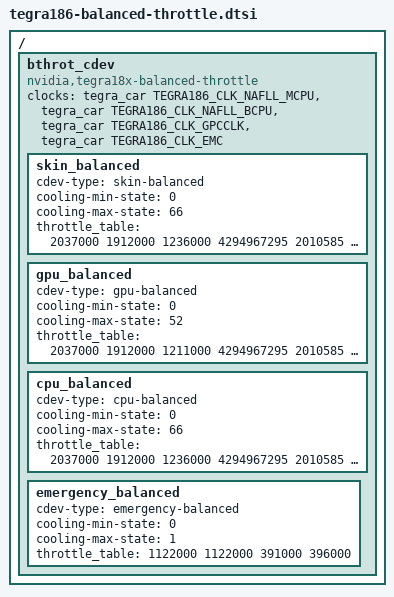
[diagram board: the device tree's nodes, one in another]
/*
 * arch/arm64/boot/dts/tegra186-platforms/tegra186-balanced-throttle.dtsi
 *
 * Copyright (c) 2015-2016, NVIDIA CORPORATION.  All rights reserved.
 *
 * This program is free software; you can redistribute it and/or modify
 * it under the terms of the GNU General Public License as published by
 * the Free Software Foundation; version 2 of the License.
 *
 * This program is distributed in the hope that it will be useful, but WITHOUT
 * ANY WARRANTY; without even the implied warranty of MERCHANTABILITY or
 * FITNESS FOR A PARTICULAR PURPOSE.  See the GNU General Public License for
 * more details.
 *
 * You should have received a copy of the GNU General Public License along
 * with this program; if not, write to the Free Software Foundation, Inc.,
 * 51 Franklin Street, Fifth Floor, Boston, MA  02110-1301, USA.
 *
 */

/{
	bthrot_cdev {
		compatible = "nvidia,tegra18x-balanced-throttle";
		clocks = <&tegra_car TEGRA186_CLK_NAFLL_MCPU>,
				 <&tegra_car TEGRA186_CLK_NAFLL_BCPU>,
				 <&tegra_car TEGRA186_CLK_GPCCLK>,
				 <&tegra_car TEGRA186_CLK_EMC>;
		clock-names = "mcpu", "bcpu", "gpu", "emc";

		skin_balanced {
			cdev-type = "skin-balanced";
			cooling-min-state = <0>;
			cooling-max-state = <66>;
			#cooling-cells = <2>;
			throttle_table = <
				2037000	1912000	1236000	4294967295
				2010585	1887508	1218508	4294967295
				1984169	1863015	1201015	4294967295
				1957754	1838523	1183523	4294967295
				1931338	1814031	1166031	4294967295
				1904923	1789538	1148538	4294967295
				1878508	1765046	1131046	4294967295
				1852092	1740554	1113554	4294967295
				1825677	1716062	1096062	4294967295
				1799262	1691569	1078569	4294967295
				1772846	1667077	1061077	4294967295
				1746431	1642585	1043585	4294967295
				1720015	1618092	1026092	4294967295
				1693600	1593600	1008600	4294967295
				1667185	1569108	991108	4294967295
				1640769	1544615	973615	4294967295
				1614354	1520123	956123	4294967295
				1587938	1495631	938631	4294967295
				1561523	1471138	921138	4294967295
				1535108	1446646	903646	4294967295
				1508692	1422154	886154	4294967295
				1482277	1397662	868662	4294967295
				1455862	1373169	851169	4294967295
				1429446	1348677	833677	4294967295
				1403031	1324185	816185	4294967295
				1376615	1299692	798692	4294967295
				1350200	1275200	781200	4294967295
				1323785	1250708	763708	4294967295
				1297369	1226215	746215	4294967295
				1270954	1201723	728723	4294967295
				1244538	1177231	711231	4294967295
				1218123	1152738	693738	4294967295
				1191708	1128246	676246	4294967295
				1165292	1103754	658754	4294967295
				1138877	1079262	641262	4294967295
				1112462	1054769	623769	4294967295
				1086046	1030277	606277	4294967295
				1059631	1005785	588785	4294967295
				1033215	981292	571292	4294967295
				1006800	956800	553800	4294967295
				980385	932308	536308	4294967295
				953969	907815	518815	4294967295
				927554	883323	501323	4294967295
				901138	858831	483831	4294967295
				874723	834338	466338	4294967295
				848308	809846	448846	4294967295
				821892	785354	431354	4294967295
				795477	760862	413862	4294967295
				769062	736369	396369	4294967295
				742646	711877	378877	4294967295
				716231	687385	361385	4294967295
				689815	662892	343892	4294967295
				663400	638400	326400	4294967295
				636985	613908	308908	4294967295
				610569	589415	291415	4294967295
				584154	564923	273923	4294967295
				557738	540431	256431	4294967295
				531323	515938	238938	4294967295
				504908	491446	221446	4294967295
				478492	466954	203954	4294967295
				452077	442462	186462	4294967295
				425662	417969	168969	4294967295
				399246	393477	151477	4294967295
				372831	368985	133985	4294967295
				346415	344492	116492	4294967295
				320000	320000	99000	4294967295
			>;
		};
		gpu_balanced {
			cdev-type = "gpu-balanced";
			cooling-min-state = <0>;
			cooling-max-state = <52>;
			#cooling-cells = <2>;
			throttle_table = <
				2037000	1912000	1211000	4294967295
				2010585	1887508	1189196	4294967295
				1984169	1863015	1167392	4294967295
				1957754	1838523	1145588	4294967295
				1931338	1814031	1123784	4294967295
				1904923	1789538	1101980	4294967295
				1878508	1765046	1080176	4294967295
				1852092	1740554	1058373	4294967295
				1825677	1716062	1036569	4294967295
				1799262	1691569	1014765	4294967295
				1772846	1667077	992961	4294967295
				1746431	1642585	971157	4294967295
				1720015	1618092	949353	4294967295
				1693600	1593600	927549	4294967295
				1667185	1569108	905745	4294967295
				1640769	1544615	883941	4294967295
				1614354	1520123	862137	4294967295
				1587938	1495631	840333	4294967295
				1561523	1471138	818529	4294967295
				1535108	1446646	796725	4294967295
				1508692	1422154	774922	4294967295
				1482277	1397662	753118	4294967295
				1455862	1373169	731314	4294967295
				1429446	1348677	709510	4294967295
				1403031	1324185	687706	4294967295
				1376615	1299692	665902	4294967295
				1350200	1275200	644098	4294967295
				1323785	1250708	622294	4294967295
				1297369	1226215	600490	4294967295
				1270954	1201723	578686	4294967295
				1244538	1177231	556882	4294967295
				1218123	1152738	535078	4294967295
				1191708	1128246	513275	4294967295
				1165292	1103754	491471	4294967295
				1138877	1079262	469667	4294967295
				1112462	1054769	447863	4294967295
				1086046	1030277	426059	4294967295
				1059631	1005785	404255	4294967295
				1033215	981292	382451	4294967295
				1006800	956800	360647	4294967295
				980385	932308	338843	4294967295
				953969	907815	317039	4294967295
				927554	883323	295235	4294967295
				901138	858831	273431	4294967295
				874723	834338	251627	4294967295
				848308	809846	229824	4294967295
				821892	785354	208020	4294967295
				795477	760862	186216	4294967295
				769062	736369	164412	4294967295
				742646	711877	142608	4294967295
				716231	687385	120804	4294967295
				689815	662892	99000	4294967295
			>;
		};
		cpu_balanced {
			cdev-type = "cpu-balanced";
			cooling-min-state = <0>;
			cooling-max-state = <66>;
			#cooling-cells = <2>;
			throttle_table = <
				2037000	1912000	1236000	4294967295
				2010585	1887508	1236000	4294967295
				1984169	1863015	1236000	4294967295
				1957754	1838523	1236000	4294967295
				1931338	1814031	1236000	4294967295
				1904923	1789538	1236000	4294967295
				1878508	1765046	1236000	4294967295
				1852092	1740554	1236000	4294967295
				1825677	1716062	1236000	4294967295
				1799262	1691569	1236000	4294967295
				1772846	1667077	1236000	4294967295
				1746431	1642585	1215327	4294967295
				1720015	1618092	1194655	4294967295
				1693600	1593600	1173982	4294967295
				1667185	1569108	1153309	4294967295
				1640769	1544615	1132636	4294967295
				1614354	1520123	1111964	4294967295
				1587938	1495631	1091291	4294967295
				1561523	1471138	1070618	4294967295
				1535108	1446646	1049945	4294967295
				1508692	1422154	1029273	4294967295
				1482277	1397662	1008600	4294967295
				1455862	1373169	987927	4294967295
				1429446	1348677	967255	4294967295
				1403031	1324185	946582	4294967295
				1376615	1299692	925909	4294967295
				1350200	1275200	905236	4294967295
				1323785	1250708	884564	4294967295
				1297369	1226215	863891	4294967295
				1270954	1201723	843218	4294967295
				1244538	1177231	822545	4294967295
				1218123	1152738	801873	4294967295
				1191708	1128246	781200	4294967295
				1165292	1103754	760527	4294967295
				1138877	1079262	739855	4294967295
				1112462	1054769	719182	4294967295
				1086046	1030277	698509	4294967295
				1059631	1005785	677836	4294967295
				1033215	981292	657164	4294967295
				1006800	956800	636491	4294967295
				980385	932308	615818	4294967295
				953969	907815	595145	4294967295
				927554	883323	574473	4294967295
				901138	858831	553800	4294967295
				874723	834338	533127	4294967295
				848308	809846	512455	4294967295
				821892	785354	491782	4294967295
				795477	760862	471109	4294967295
				769062	736369	450436	4294967295
				742646	711877	429764	4294967295
				716231	687385	409091	4294967295
				689815	662892	388418	4294967295
				663400	638400	367745	4294967295
				636985	613908	347073	4294967295
				610569	589415	326400	4294967295
				584154	564923	305727	4294967295
				557738	540431	285055	4294967295
				531323	515938	264382	4294967295
				504908	491446	243709	4294967295
				478492	466954	223036	4294967295
				452077	442462	202364	4294967295
				425662	417969	181691	4294967295
				399246	393477	161018	4294967295
				372831	368985	140345	4294967295
				346415	344492	119673	4294967295
				320000	320000	99000	4294967295
			>;
		};
		emergency_balanced {
			cdev-type = "emergency-balanced";
			cooling-min-state = <0>;
			cooling-max-state = <1>;
			#cooling-cells = <2>;
			throttle_table = <
				1122000	1122000	391000	396000
			>;
		};
	};
};
